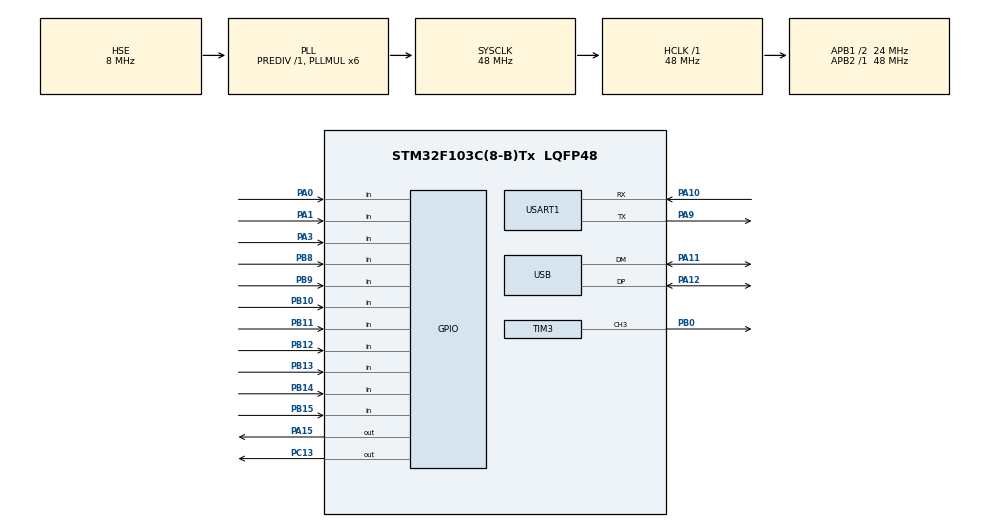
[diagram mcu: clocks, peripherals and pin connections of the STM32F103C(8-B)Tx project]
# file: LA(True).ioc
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Dma.Request0=USART1_RX
Dma.Request1=USART1_TX
Dma.USART1_RX.0.Direction=DMA_PERIPH_TO_MEMORY
Dma.USART1_RX.0.Instance=DMA1_Channel5
Dma.USART1_RX.0.MemDataAlignment=DMA_MDATAALIGN_BYTE
Dma.USART1_RX.0.MemInc=DMA_MINC_ENABLE
Dma.USART1_RX.0.Mode=DMA_NORMAL
Dma.USART1_RX.0.PeriphDataAlignment=DMA_PDATAALIGN_BYTE
Dma.USART1_RX.0.PeriphInc=DMA_PINC_DISABLE
Dma.USART1_RX.0.Priority=DMA_PRIORITY_LOW
Dma.USART1_TX.1.Direction=DMA_MEMORY_TO_PERIPH
Dma.USART1_TX.1.Instance=DMA1_Channel4
Dma.USART1_TX.1.MemDataAlignment=DMA_MDATAALIGN_BYTE
Dma.USART1_TX.1.MemInc=DMA_MINC_ENABLE
Dma.USART1_TX.1.Mode=DMA_NORMAL
Dma.USART1_TX.1.PeriphDataAlignment=DMA_PDATAALIGN_BYTE
Dma.USART1_TX.1.PeriphInc=DMA_PINC_DISABLE
Dma.USART1_TX.1.Priority=DMA_PRIORITY_LOW
Mcu.Family=STM32F1
Mcu.Name=STM32F103C(8-B)Tx
Mcu.Package=LQFP48
NVIC.DMA1_Channel4_IRQn=true\:0\:0\:false\:false\:true\:false\:true\:true
NVIC.DMA1_Channel5_IRQn=true\:0\:0\:false\:false\:true\:false\:true\:true
NVIC.PriorityGroup=NVIC_PRIORITYGROUP_4
NVIC.TIM3_IRQn=true\:0\:0\:false\:false\:true\:true\:true\:true
NVIC.TIM4_IRQn=true\:15\:0\:false\:false\:true\:false\:true\:true
NVIC.TimeBase=TIM4_IRQn
NVIC.TimeBaseIP=TIM4
NVIC.USART1_IRQn=true\:0\:0\:false\:false\:true\:false\:true\:true
NVIC.USB_HP_CAN1_TX_IRQn=true\:0\:0\:false\:false\:true\:true\:true\:true
NVIC.USB_LP_CAN1_RX0_IRQn=true\:0\:0\:false\:false\:true\:true\:true\:true
PA0-WKUP.GPIO_PuPd=GPIO_PULLUP
PA0-WKUP.Signal=GPIO_Input
PA1.GPIO_PuPd=GPIO_PULLUP
PA1.Signal=GPIO_Input
PA10.Mode=Asynchronous
PA10.Signal=USART1_RX
PA11.Mode=Device
PA11.Signal=USB_DM
PA12.Mode=Device
PA12.Signal=USB_DP
PA13.Mode=Serial_Wire
PA13.Signal=SYS_JTMS-SWDIO
PA14.Mode=Serial_Wire
PA14.Signal=SYS_JTCK-SWCLK
PA15.Signal=GPIO_Output
PA3.GPIO_PuPd=GPIO_PULLUP
PA3.Signal=GPIO_Input
PA9.Mode=Asynchronous
PA9.Signal=USART1_TX
PB0.Signal=S_TIM3_CH3
PB10.GPIO_PuPd=GPIO_PULLUP
PB10.Signal=GPIO_Input
PB11.GPIO_PuPd=GPIO_PULLUP
PB11.Signal=GPIO_Input
PB12.GPIO_PuPd=GPIO_PULLUP
PB12.Signal=GPIO_Input
PB13.GPIO_PuPd=GPIO_PULLUP
PB13.Signal=GPIO_Input
PB14.GPIO_PuPd=GPIO_PULLUP
PB14.Signal=GPIO_Input
PB15.GPIO_PuPd=GPIO_PULLUP
PB15.Signal=GPIO_Input
PB8.GPIO_PuPd=GPIO_PULLUP
PB8.Signal=GPIO_Input
PB9.GPIO_PuPd=GPIO_PULLUP
PB9.Signal=GPIO_Input
PC13-TAMPER-RTC.Signal=GPIO_Output
PC14-OSC32_IN.Mode=LSE-External-Oscillator
PC14-OSC32_IN.Signal=RCC_OSC32_IN
PC15-OSC32_OUT.Mode=LSE-External-Oscillator
PC15-OSC32_OUT.Signal=RCC_OSC32_OUT
PD0-OSC_IN.Mode=HSE-External-Oscillator
PD0-OSC_IN.Signal=RCC_OSC_IN
PD1-OSC_OUT.Mode=HSE-External-Oscillator
PD1-OSC_OUT.Signal=RCC_OSC_OUT
ProjectManager.HeapSize=0x200
ProjectManager.StackSize=0x400
ProjectManager.TargetToolchain=MDK-ARM V5
RCC.AHBFreq_Value=48000000
RCC.APB1CLKDivider=RCC_HCLK_DIV2
RCC.APB1Freq_Value=24000000
RCC.APB1TimFreq_Value=48000000
RCC.APB2Freq_Value=48000000
RCC.APB2TimFreq_Value=48000000
RCC.HCLKFreq_Value=48000000
RCC.PLLMUL=RCC_PLL_MUL6
RCC.PLLSourceVirtual=RCC_PLLSOURCE_HSE
RCC.SYSCLKFreq_VALUE=48000000
RCC.SYSCLKSource=RCC_SYSCLKSOURCE_PLLCLK
RCC.USBFreq_Value=48000000
SH.S_TIM3_CH3.0=TIM3_CH3,PWM Generation3 CH3
TIM2.Period=2000-1
TIM2.Prescaler=359
TIM3.Channel-PWM\ Generation3\ CH3=TIM_CHANNEL_3
TIM3.Period=1000-1
TIM3.Prescaler=72-1
TIM3.Pulse-PWM\ Generation3\ CH3=500
USART1.VirtualMode=VM_ASYNC
USB_DEVICE.CLASS_NAME_FS=CDC
USB_DEVICE.VirtualMode=Cdc
USB_DEVICE.VirtualModeFS=Cdc_FS
VP_SYS_VS_tim4.Mode=TIM4
VP_TIM2_VS_ClockSourceINT.Mode=Internal
VP_TIM3_VS_ClockSourceINT.Mode=Internal
VP_USB_DEVICE_VS_USB_DEVICE_CDC_FS.Mode=CDC_FS
board=custom

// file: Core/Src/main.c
/* USER CODE BEGIN Header */
/**
  ******************************************************************************
  * @file           : main.c
  * @brief          : Main program body
  ******************************************************************************
  * @attention
  *
  * Copyright (c) 2025 STMicroelectronics.
  * All rights reserved.
  *
  * This software is licensed under terms that can be found in the LICENSE file
  * in the root directory of this software component.
  * If no LICENSE file comes with this software, it is provided AS-IS.
  *
  ******************************************************************************
  */
/* USER CODE END Header */
#include "main.h"
#include "dma.h"
#include "tim.h"
#include "usart.h"
#include "usb_device.h"
#include "gpio.h"

/* USER CODE BEGIN Includes */
//#include "la_hw.h"
#include "la_sump.h"
#include "circle_buffer.h"
//#include "oled.h"
/* USER CODE END Includes */

void SystemClock_Config(void);

/* USER CODE BEGIN 0 */
extern void Time_Measure(void);

//void TimeMeasure(void)
//{
//	//0.output 0
//	HAL_GPIO_WritePin(GPIOA, GPIO_PIN_12, GPIO_PIN_RESET);
//	HAL_Delay(100);
//	//1.shut intr down
//	__disable_irq();
//	//2.(1)set
//	//HAL_GPIO_WritePin(GPIOA, GPIO_PIN_12, GPIO_PIN_SET);
//
//	//(2)run
//	Time_Measure();
//
//	//(3)reset
//	//HAL_GPIO_WritePin(GPIOA, GPIO_PIN_12, GPIO_PIN_RESET);
//	//3.open intr
//	__enable_irq();
//}
/* USER CODE END 0 */

int main(void)
{

  /* MCU Configuration--------------------------------------------------------*/

  /* Reset of all peripherals, Initializes the Flash interface and the Systick. */
  HAL_Init();

  /* Configure the system clock */
  SystemClock_Config();

  /* Initialize all configured peripherals */
  MX_GPIO_Init();
  MX_DMA_Init();
  MX_USART1_UART_Init();
  MX_TIM2_Init();
  MX_TIM3_Init();
  MX_USB_DEVICE_Init();
  /* USER CODE BEGIN 2 */

  /*la*/
  Circle_Buf_Init(&g_uart_rx_bufs, 100, g_RecvBuf);
  	LA_Init();

//  /*oled*/

//	HAL_Delay(20);
//	OLED_Init();
////	OLED_DisPlay_Off();
////	HAL_Delay(10);
////	OLED_DisPlay_On();
//
//	OLED_NewFrame();
//	OLED_PrintASCIIString(10,10,"YUQIRI",&afont12x6,OLED_COLOR_NORMAL);
//	OLED_ShowFrame();

  /*pwm light*/

//	HAL_TIM_PWM_Start(&htim2,TIM_CHANNEL_1);
//	HAL_TIM_PWM_Start(&htim2,TIM_CHANNEL_2);
//	HAL_TIM_PWM_Start(&htim2,TIM_CHANNEL_3);
//	uint32_t dutycount = 600;
//	uint32_t duty = dutycount / 2000;

  /* USER CODE END 2 */

  /* Infinite loop */
  /* USER CODE BEGIN WHILE */

  while (1)
  {
	HAL_TIM_PWM_Start(&htim3,TIM_CHANNEL_3);
	//TimeMeasure();
	LogicalAnalyser();
//	__HAL_TIM_SET_COMPARE(&htim2,TIM_CHANNEL_1,dutycount);
//	__HAL_TIM_SET_COMPARE(&htim2,TIM_CHANNEL_1,dutycount);
//	HAL_Delay(500);
//	dutycount = 0;
//	__HAL_TIM_SET_COMPARE(&htim2,TIM_CHANNEL_1,dutycount);
//	HAL_Delay(500);
//	dutycount = 1800;
//	__HAL_TIM_SET_COMPARE(&htim2,TIM_CHANNEL_1,dutycount);
//	__HAL_TIM_SET_COMPARE(&htim2,TIM_CHANNEL_2,300);

//  if(duty < 100 && duty > 30){
//  	htim2.Instance->CCR1 = duty++;}
//	else if(duty >= 100){
//	htim2.Instance->CCR1 = duty--;}
//	else if(duty <= 30){
//	htim2.Instance->CCR1 = duty++;}

    /* USER CODE END WHILE */

  }
}

void SystemClock_Config(void)
{
  RCC_OscInitTypeDef RCC_OscInitStruct = {0};
  RCC_ClkInitTypeDef RCC_ClkInitStruct = {0};
  RCC_PeriphCLKInitTypeDef PeriphClkInit = {0};

  /** Initializes the RCC Oscillators according to the specified parameters
  * in the RCC_OscInitTypeDef structure.
  */
  RCC_OscInitStruct.OscillatorType = RCC_OSCILLATORTYPE_HSE;
  RCC_OscInitStruct.HSEState = RCC_HSE_ON;
  RCC_OscInitStruct.HSEPredivValue = RCC_HSE_PREDIV_DIV1;
  RCC_OscInitStruct.HSIState = RCC_HSI_ON;
  RCC_OscInitStruct.PLL.PLLState = RCC_PLL_ON;
  RCC_OscInitStruct.PLL.PLLSource = RCC_PLLSOURCE_HSE;
  RCC_OscInitStruct.PLL.PLLMUL = RCC_PLL_MUL6;
  if (HAL_RCC_OscConfig(&RCC_OscInitStruct) != HAL_OK)
  {
    Error_Handler();
  }

  /** Initializes the CPU, AHB and APB buses clocks
  */
  RCC_ClkInitStruct.ClockType = RCC_CLOCKTYPE_HCLK|RCC_CLOCKTYPE_SYSCLK
                              |RCC_CLOCKTYPE_PCLK1|RCC_CLOCKTYPE_PCLK2;
  RCC_ClkInitStruct.SYSCLKSource = RCC_SYSCLKSOURCE_PLLCLK;
  RCC_ClkInitStruct.AHBCLKDivider = RCC_SYSCLK_DIV1;
  RCC_ClkInitStruct.APB1CLKDivider = RCC_HCLK_DIV2;
  RCC_ClkInitStruct.APB2CLKDivider = RCC_HCLK_DIV1;

  if (HAL_RCC_ClockConfig(&RCC_ClkInitStruct, FLASH_LATENCY_1) != HAL_OK)
  {
    Error_Handler();
  }
  PeriphClkInit.PeriphClockSelection = RCC_PERIPHCLK_USB;
  PeriphClkInit.UsbClockSelection = RCC_USBCLKSOURCE_PLL;
  if (HAL_RCCEx_PeriphCLKConfig(&PeriphClkInit) != HAL_OK)
  {
    Error_Handler();
  }
}

void HAL_TIM_PeriodElapsedCallback(TIM_HandleTypeDef *htim)
{
  if (htim->Instance == TIM4)
  {
    HAL_IncTick();
  }
}

void Error_Handler(void)
{
  __disable_irq();
  while (1)
  {
  }
}
